# STM32WB07 register map
File version: 1.0
CPU: CM0+ r0p0, little endian, MPU, no FPU, 2 interrupt priority bits
Registers are 32-bit, read-write, reset 0x0 unless marked. A register's access mark holds for its fields unless they carry their own. Offsets are from the block's base; [hi:lo] are bit positions; lines under a group give offsets from that group; {n}, {i} and the like mark numbered series; 'fields as' and 'values as' point back to an identical list.

## DMA
Base 0x48700000
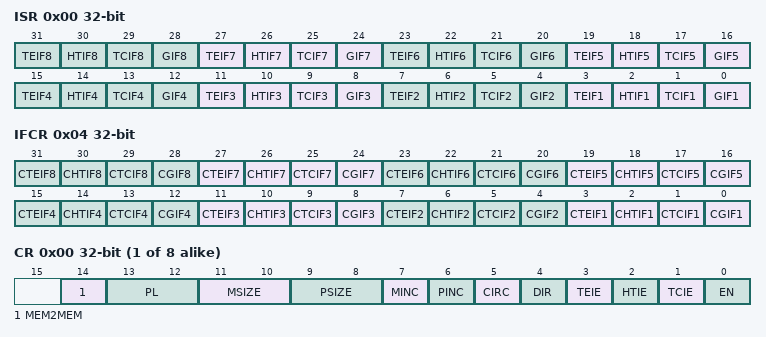
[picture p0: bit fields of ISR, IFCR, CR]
0x00 ISR ro — DMA_ISR register
  [4n-1] TEIF{n} (n=1..8) — Channel {n} Transfer Error flag
    0=NoError (No transfer error); 1=Error (A transfer error has occured)
  [4n-2] HTIF{n} (n=1..8) — Channel {n} Half Transfer Complete flag
    0=NotHalf (No half transfer event); 1=Half (A half transfer event has occured)
  [4n-3] TCIF{n} (n=1..8) — Channel {n} Transfer Complete flag
    0=NotComplete (No transfer complete event); 1=Complete (A transfer complete event has occured)
  [4n-4] GIF{n} (n=1..8) — Channel {n} Global interrupt flag
    0=NoEvent (No transfer error, half event, complete event); 1=Event (A transfer error, half event or complete event has occured)
0x04 IFCR wo — DMA_IFCR register
  [4n-1] CTEIF{n} (n=1..8) — Channel {n} Transfer Error clear
    1=Clears the TEIF flag in the ISR register
  [4n-2] CHTIF{n} (n=1..8) — Channel {n} Half Transfer clear
    1=Clears the HTIF flag in the ISR register
  [4n-3] CTCIF{n} (n=1..8) — Channel {n} Transfer Complete clear
    1=Clears the TCIF flag in the ISR register
  [4n-4] CGIF{n} (n=1..8) — Channel {n} Global interrupt clear
    1=Clears the GIF, TEIF, HTIF, TCIF flags in the ISR register
0x08 CH{i} (i=1..8; step 0x14) group — Channel cluster: CCR?, CNDTR?, CPAR?, and CMAR? registers
  0x00 CR — DMA_CCRx register
    [14] MEM2MEM — MEM2MEM: Memory to memory mode This bit is set and cleared by software. 0: Memory to memory mode disabled 1: Memory to memory mode enabled
      0=Disabled (Memory to memory mode disabled); 1=Enabled (Memory to memory mode enabled)
    [13:12] PL — PL[1:0]: Channel priority level These bits are set and cleared by software. 00: Low 01: Medium 10: High 11: Very high
      0=Low (Low priority); 1=Medium priority; 2=High priority; 3=Very high priority
    [11:10] MSIZE — MSIZE[1:0]: Memory size These bits are set and cleared by software. 00: 8-bits 01: 16-bits 10: 32-bits
      0=Bits8 (8-bit size); 1=Bits16 (16-bit size); 2=Bits32 (32-bit size)
    [9:8] PSIZE — PSIZE[1:0]: Peripheral size These bits are set and cleared by software. 00: 8-bits 01: 16-bits 10: 32-bits
      values as MSIZE
    [7] MINC — MINC: Memory increment mode This bit is set and cleared by software. 0: Memory increment mode disabled 1: Memory increment mode enabled
      0=Disabled (Increment mode disabled); 1=Enabled (Increment mode enabled)
    [6] PINC — PINC: Peripheral increment mode This bit is set and cleared by software. 0: Peripheral increment mode disabled 1: Peripheral increment mode enabled
      values as MINC
    [5] CIRC — CIRC: Circular mode This bit is set and cleared by software. 0: Circular mode disabled 1: Circular mode enabled
      0=Disabled (Circular buffer disabled); 1=Enabled (Circular buffer enabled)
    [4] DIR — DIR: Data transfer direction This bit is set and cleared by software. 0: Read from peripheral 1: Read from memory
      0=FromPeripheral (Read from peripheral); 1=FromMemory (Read from memory)
    [3] TEIE — TEIE: Transfer error interrupt enable This bit is set and cleared by software. 0: TE interrupt disabled 1: TE interrupt enabled
      0=Disabled (Transfer Error interrupt disabled); 1=Enabled (Transfer Error interrupt enabled)
    [2] HTIE — HTIE: Half transfer interrupt enable This bit is set and cleared by software. 0: HT interrupt disabled 1: HT interrupt enabled
      0=Disabled (Half Transfer interrupt disabled); 1=Enabled (Half Transfer interrupt enabled)
    [1] TCIE — TCIE: Transfer complete interrupt enable This bit is set and cleared by software. 0: TC interrupt disabled 1: TC interrupt enabled
      0=Disabled (Transfer Complete interrupt disabled); 1=Enabled (Transfer Complete interrupt enabled)
    [0] EN — EN: Channel enable This bit is set and cleared by software. 0: Channel disabled 1: Channel enabled
      0=Disabled (Channel disabled); 1=Enabled (Channel enabled)
  0x04 NDTR — DMA_CNDTRx register
    [15:0] NDT — NDT[15:0]: Number of data to transfer Number of data to be transferred (0 up to 65535). This register can only be written when the channel is disabled. Once the channel is enabled, this register is read-only, indicating the remaining bytes to be transmitted. This register decrements after each DMA transfer. Once the transfer is completed, this register can either stay at zero or be reloaded automatically by the value previously programmed if the channel is configured in auto-reload mode. If this register is zero, no transaction can be served whether the channel is enabled or not.
  0x08 PAR — DMA_CPARx register
    [31:0] PA — PA[31:0]: Peripheral address Base address of the peripheral data register from/to which the data will be read/written. When PSIZE is 01 (16-bit), the PA[0] bit is ignored. Access is automatically aligned to a halfword address. When PSIZE is 10 (32-bit), PA[1:0] are ignored. Access is automatically aligned to a word address.
  0x0C MAR — DMA_CMARx register
    [31:0] MA — MA[31:0]: Memory address Base address of the memory area from/to which the data will be read/written. When MSIZE is 01 (16-bit), the MA[0] bit is ignored. Access is automatically aligned to a halfword address. When MSIZE is 10 (32-bit), MA[1:0] are ignored. Access is automatically aligned to a word address.
